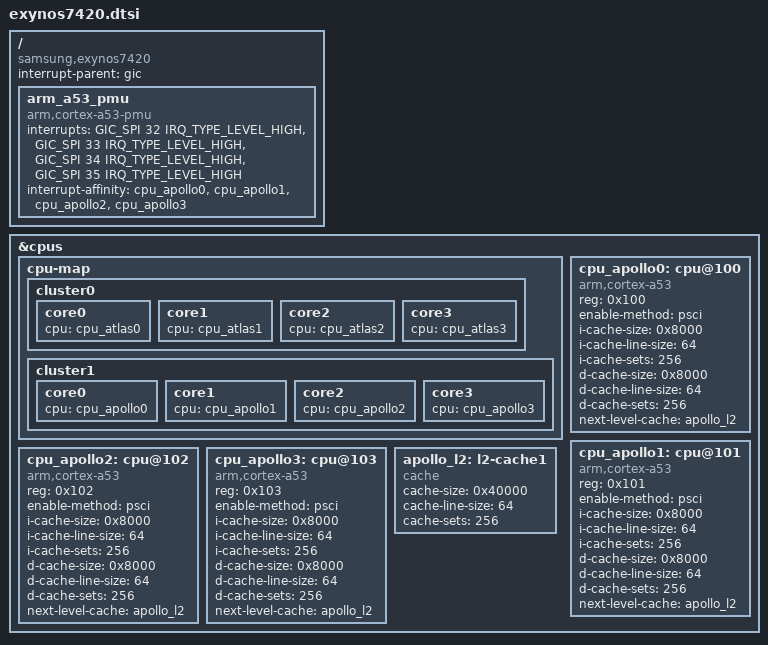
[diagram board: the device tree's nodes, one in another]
// SPDX-License-Identifier: GPL-2.0
/*
 * Samsung Exynos7420 SoC device tree source
 *
 * It's basically Exynos7 with additional 4 x A53 cores.
 */

/dts-v1/;
#include "exynos7.dtsi"

/ {
	compatible = "samsung,exynos7420", "samsung,exynos7";
	interrupt-parent = <&gic>;
	#address-cells = <2>;
	#size-cells = <2>;

	arm_a53_pmu {
		compatible = "arm,cortex-a53-pmu";
		interrupts = <GIC_SPI 32 IRQ_TYPE_LEVEL_HIGH>,
			     <GIC_SPI 33 IRQ_TYPE_LEVEL_HIGH>,
			     <GIC_SPI 34 IRQ_TYPE_LEVEL_HIGH>,
			     <GIC_SPI 35 IRQ_TYPE_LEVEL_HIGH>;
		interrupt-affinity = <&cpu_apollo0>, <&cpu_apollo1>,
				     <&cpu_apollo2>, <&cpu_apollo3>;
	};
};

&cpus {

	cpu-map {
			cluster0 {
				core0 {
					cpu = <&cpu_atlas0>;
				};
				core1 {
					cpu = <&cpu_atlas1>;
				};
				core2 {
					cpu = <&cpu_atlas2>;
				};
				core3 {
					cpu = <&cpu_atlas3>;
				};
			};

			cluster1 {
				core0 {
					cpu = <&cpu_apollo0>;
				};
				core1 {
					cpu = <&cpu_apollo1>;
				};
				core2 {
					cpu = <&cpu_apollo2>;
				};
				core3 {
					cpu = <&cpu_apollo3>;
				};
			};
		};

    cpu_apollo0: cpu@100 {
        device_type = "cpu";
        compatible = "arm,cortex-a53";
        reg = <0x100>;
        enable-method = "psci";
	i-cache-size = <0x8000>;
        i-cache-line-size = <64>;
        i-cache-sets = <256>;
        d-cache-size = <0x8000>;
        d-cache-line-size = <64>;
        d-cache-sets = <256>;
        next-level-cache = <&apollo_l2>;
    };

    cpu_apollo1: cpu@101 {
        device_type = "cpu";
        compatible = "arm,cortex-a53";
        reg = <0x101>;
        enable-method = "psci";
        i-cache-size = <0x8000>;
        i-cache-line-size = <64>;
        i-cache-sets = <256>;
        d-cache-size = <0x8000>;
        d-cache-line-size = <64>;
        d-cache-sets = <256>;
        next-level-cache = <&apollo_l2>;
    };

    cpu_apollo2: cpu@102 {
        device_type = "cpu";
        compatible = "arm,cortex-a53";
        reg = <0x102>;
        enable-method = "psci";
	i-cache-size = <0x8000>;
        i-cache-line-size = <64>;
        i-cache-sets = <256>;
        d-cache-size = <0x8000>;
        d-cache-line-size = <64>;
        d-cache-sets = <256>; 
        next-level-cache = <&apollo_l2>;
    };

    cpu_apollo3: cpu@103 {
        device_type = "cpu";
        compatible = "arm,cortex-a53";
        reg = <0x103>;
        enable-method = "psci";
	i-cache-size = <0x8000>;
        i-cache-line-size = <64>;
        i-cache-sets = <256>;
        d-cache-size = <0x8000>;
        d-cache-line-size = <64>;
        d-cache-sets = <256>; 
        next-level-cache = <&apollo_l2>;
    };

	apollo_l2: l2-cache1 {
			compatible = "cache";
			cache-size = <0x40000>;
			cache-line-size = <64>;
			cache-sets = <256>;
		};

};
